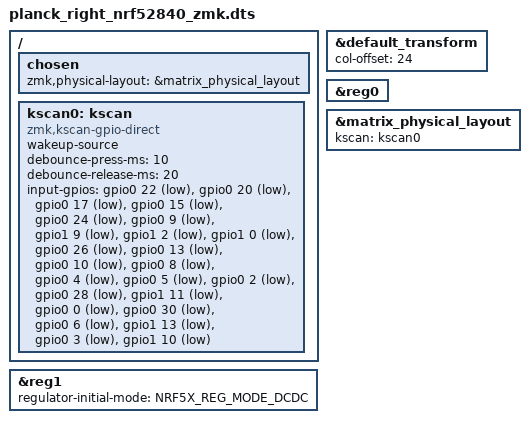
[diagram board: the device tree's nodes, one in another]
/dts-v1/;
#include "planck.dtsi"
#include "leds.dtsi"
#include <common/nordic/nrf52840_uf2_boot_mode.dtsi>


&default_transform {
	col-offset = <24>;
};
&reg0 {
    status = "okay";
};
&reg1 {
    regulator-initial-mode = <NRF5X_REG_MODE_DCDC>;
};

&matrix_physical_layout {
  	kscan = <&kscan0>;
};

/ {
    chosen {
        zmk,physical-layout = &matrix_physical_layout;
    };
    kscan0: kscan {
        compatible = "zmk,kscan-gpio-direct";
        wakeup-source;
        debounce-press-ms = <10>;
        debounce-release-ms = <20>;
        input-gpios =
            <&gpio0 22 (GPIO_ACTIVE_LOW | GPIO_PULL_UP)>,  // 19
            <&gpio0 20 (GPIO_ACTIVE_LOW | GPIO_PULL_UP)>,  // 18
            <&gpio0 17 (GPIO_ACTIVE_LOW | GPIO_PULL_UP)>,  // 13
            <&gpio0 15 (GPIO_ACTIVE_LOW | GPIO_PULL_UP)>,  // 12
            <&gpio0 24 (GPIO_ACTIVE_LOW | GPIO_PULL_UP)>,  // 5
            <&gpio0  9 (GPIO_ACTIVE_LOW | GPIO_PULL_UP)>,  // 5
            <&gpio1  9 (GPIO_ACTIVE_LOW | GPIO_PULL_UP)>,  // 4
            <&gpio1  2 (GPIO_ACTIVE_LOW | GPIO_PULL_UP)>,  // ex1
            <&gpio1  0 (GPIO_ACTIVE_LOW | GPIO_PULL_UP)>,  // 20
            <&gpio0 26 (GPIO_ACTIVE_LOW | GPIO_PULL_UP)>,  // 17
            <&gpio0 13 (GPIO_ACTIVE_LOW | GPIO_PULL_UP)>,  // 14
            <&gpio0 10 (GPIO_ACTIVE_LOW | GPIO_PULL_UP)>,  // 14
            <&gpio0  8 (GPIO_ACTIVE_LOW | GPIO_PULL_UP)>,  // 11
            <&gpio0  4 (GPIO_ACTIVE_LOW | GPIO_PULL_UP)>,  // 6
            <&gpio0  5 (GPIO_ACTIVE_LOW | GPIO_PULL_UP)>,  // 3
            <&gpio0  2 (GPIO_ACTIVE_LOW | GPIO_PULL_UP)>,  // ex2
            <&gpio0 28 (GPIO_ACTIVE_LOW | GPIO_PULL_UP)>,  // 21
            <&gpio1 11 (GPIO_ACTIVE_LOW | GPIO_PULL_UP)>,  // 16
            <&gpio0  0 (GPIO_ACTIVE_LOW | GPIO_PULL_UP)>,  // 2
            <&gpio0 30 (GPIO_ACTIVE_LOW | GPIO_PULL_UP)>,  // 7
            <&gpio0  6 (GPIO_ACTIVE_LOW | GPIO_PULL_UP)>,  // 10
            <&gpio1 13 (GPIO_ACTIVE_LOW | GPIO_PULL_UP)>,  // 15
            <&gpio0  3 (GPIO_ACTIVE_LOW | GPIO_PULL_UP)>,  // 15
            <&gpio1 10 (GPIO_ACTIVE_LOW | GPIO_PULL_UP)>;  // 15
    };
};
